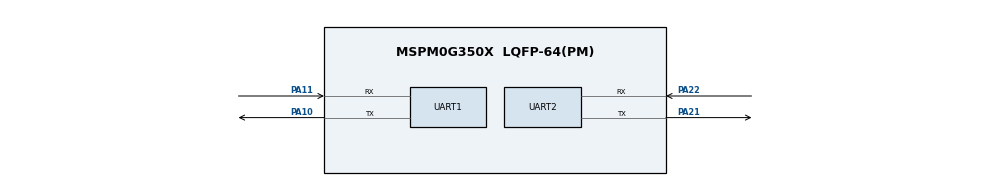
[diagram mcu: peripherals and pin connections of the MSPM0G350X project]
/**
 * @cliArgs --device "MSPM0G350X" --part "Default" --package "LQFP-64(PM)" --product "mspm0_sdk@2.02.00.05"
 * @versions {"tool":"1.21.1+3772"}
 */

/**
 * Import the modules used in this configuration.
 */
const GPIO   = scripting.addModule("/ti/driverlib/GPIO", {}, false);
const GPIO1  = GPIO.addInstance();
const SYSCTL = scripting.addModule("/ti/driverlib/SYSCTL");
const UART   = scripting.addModule("/ti/driverlib/UART", {}, false);
const UART1  = UART.addInstance();
const UART2  = UART.addInstance();

/**
 * Write custom configuration values to the imported modules.
 */
const gate7  = system.clockTree["MFCLKGATE"];
gate7.enable = true;

GPIO1.$name                         = "LED1";
GPIO1.port                          = "PORTB";
GPIO1.associatedPins[0].$name       = "PIN_2";
GPIO1.associatedPins[0].assignedPin = "2";

const Board = scripting.addModule("/ti/driverlib/Board", {}, false);

SYSCTL.forceDefaultClkConfig = true;
SYSCTL.clockTreeEn           = true;

UART1.$name                    = "UART_0";
UART1.enabledInterrupts        = ["RX"];
UART1.targetBaudRate           = 115200;
UART1.uartClkSrc               = "MFCLK";
UART1.peripheral.rxPin.$assign = "PA11";
UART1.peripheral.txPin.$assign = "PA10";
UART1.txPinConfig.$name        = "ti_driverlib_gpio_GPIOPinGeneric0";
UART1.rxPinConfig.$name        = "ti_driverlib_gpio_GPIOPinGeneric1";

UART2.$name                            = "UART_2";
UART2.targetBaudRate                   = 115200;
UART2.enabledInterrupts                = ["RX"];
UART2.peripheral.$assign               = "UART2";
UART2.peripheral.rxPin.$assign         = "PA22";
UART2.peripheral.txPin.$assign         = "PA21";
UART2.txPinConfig.$name                = "ti_driverlib_gpio_GPIOPinGeneric2";
UART2.txPinConfig.direction            = scripting.forceWrite("OUTPUT");
UART2.txPinConfig.hideOutputInversion  = scripting.forceWrite(false);
UART2.txPinConfig.onlyInternalResistor = scripting.forceWrite(false);
UART2.txPinConfig.passedPeripheralType = scripting.forceWrite("Digital");
UART2.rxPinConfig.$name                = "ti_driverlib_gpio_GPIOPinGeneric3";
UART2.rxPinConfig.hideOutputInversion  = scripting.forceWrite(false);
UART2.rxPinConfig.onlyInternalResistor = scripting.forceWrite(false);
UART2.rxPinConfig.passedPeripheralType = scripting.forceWrite("Digital");

/**
 * Pinmux solution for unlocked pins/peripherals. This ensures that minor changes to the automatic solver in a future
 * version of the tool will not impact the pinmux you originally saw.  These lines can be completely deleted in order to
 * re-solve from scratch.
 */
GPIO1.associatedPins[0].pin.$suggestSolution = "PB2";
Board.peripheral.$suggestSolution            = "DEBUGSS";
Board.peripheral.swclkPin.$suggestSolution   = "PA20";
Board.peripheral.swdioPin.$suggestSolution   = "PA19";
UART1.peripheral.$suggestSolution            = "UART0";
